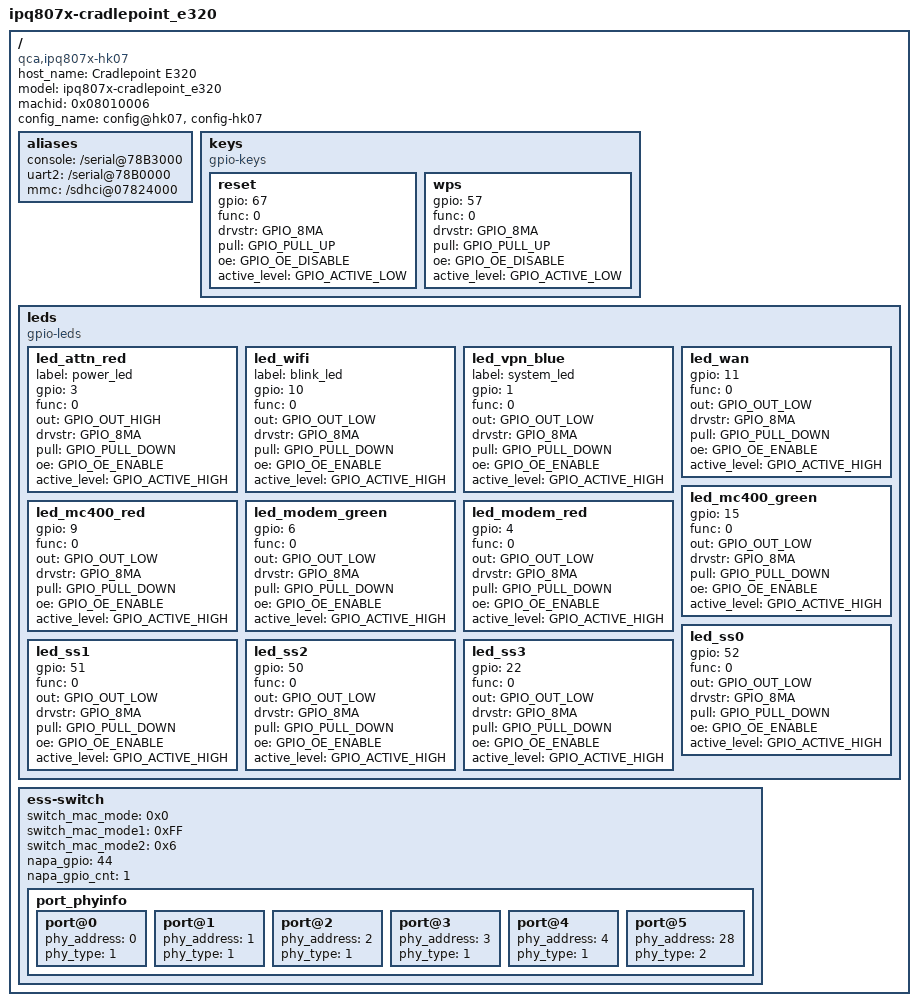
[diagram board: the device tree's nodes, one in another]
/*
 * Copyright (c) 2016 - 2018, The Linux Foundation. All rights reserved.
 *
 * This program is free software; you can redistribute it and/or modify
 * it under the terms of the GNU General Public License version 2 and
 * only version 2 as published by the Free Software Foundation.
 *
 * This program is distributed in the hope that it will be useful,
 * but WITHOUT ANY WARRANTY; without even the implied warranty of
 * MERCHANTABILITY or FITNESS FOR A PARTICULAR PURPOSE.  See the
 * GNU General Public License for more details.
 */

/dts-v1/;
#include "ipq807x-soc.dtsi"
#include <dt-bindings/qcom/gpio-ipq807x.h>
/ {
    host_name = "Cradlepoint E320";
	model = "ipq807x-cradlepoint_e320";
	compatible = "qca,ipq807x-hk07", "qca,ipq807x";
	machid = <0x08010006>;
	config_name = "config@hk07", "config-hk07";

	aliases {
		console = "/serial@78B3000";
		uart2 = "/serial@78B0000";
		mmc = "/sdhci@07824000";
	};

    keys {
		compatible = "gpio-keys";

        reset {
            gpio = <67>;
            func = <0>;
            drvstr = <GPIO_8MA>;
            pull = <GPIO_PULL_UP>;
            oe = <GPIO_OE_DISABLE>;
			active_level = <GPIO_ACTIVE_LOW>;
        };

        wps {
            gpio = <57>;
            func = <0>;
            drvstr = <GPIO_8MA>;
            pull = <GPIO_PULL_UP>;
            oe = <GPIO_OE_DISABLE>;
			active_level = <GPIO_ACTIVE_LOW>;
        };
    };

    leds {
		compatible = "gpio-leds";

        led_attn_red {
			label = "power_led";
            gpio = <3>;
            func = <0>;
            out = <GPIO_OUT_HIGH>;
            drvstr = <GPIO_8MA>;
            pull = <GPIO_PULL_DOWN>;
            oe = <GPIO_OE_ENABLE>;
            active_level = <GPIO_ACTIVE_HIGH>;
        };

        led_wifi {
			label = "blink_led";
            gpio = <10>;
            func = <0>;
            out = <GPIO_OUT_LOW>;
            drvstr = <GPIO_8MA>;
            pull = <GPIO_PULL_DOWN>;
            oe = <GPIO_OE_ENABLE>;
            active_level = <GPIO_ACTIVE_HIGH>;
        };

        led_vpn_blue {
			label = "system_led";
            gpio = <1>;
            func = <0>;
            out = <GPIO_OUT_LOW>;
            drvstr = <GPIO_8MA>;
            pull = <GPIO_PULL_DOWN>;
            oe = <GPIO_OE_ENABLE>;
            active_level = <GPIO_ACTIVE_HIGH>;
        };

        led_wan {
            gpio = <11>;
            func = <0>;
            out = <GPIO_OUT_LOW>;
            drvstr = <GPIO_8MA>;
            pull = <GPIO_PULL_DOWN>;
            oe = <GPIO_OE_ENABLE>;
            active_level = <GPIO_ACTIVE_HIGH>;
        };

        led_mc400_green {
            gpio = <15>;
            func = <0>;
            out = <GPIO_OUT_LOW>;
            drvstr = <GPIO_8MA>;
            pull = <GPIO_PULL_DOWN>;
            oe = <GPIO_OE_ENABLE>;
            active_level = <GPIO_ACTIVE_HIGH>;
        };

        led_mc400_red {
            gpio = <9>;
            func = <0>;
            out = <GPIO_OUT_LOW>;
            drvstr = <GPIO_8MA>;
            pull = <GPIO_PULL_DOWN>;
            oe = <GPIO_OE_ENABLE>;
            active_level = <GPIO_ACTIVE_HIGH>;
        };

        led_modem_green {
            gpio = <6>;
            func = <0>;
            out = <GPIO_OUT_LOW>;
            drvstr = <GPIO_8MA>;
            pull = <GPIO_PULL_DOWN>;
            oe = <GPIO_OE_ENABLE>;
            active_level = <GPIO_ACTIVE_HIGH>;
        };

        led_modem_red {
            gpio = <4>;
            func = <0>;
            out = <GPIO_OUT_LOW>;
            drvstr = <GPIO_8MA>;
            pull = <GPIO_PULL_DOWN>;
            oe = <GPIO_OE_ENABLE>;
            active_level = <GPIO_ACTIVE_HIGH>;
        };

        led_ss0 {
            gpio = <52>;
            func = <0>;
            out = <GPIO_OUT_LOW>;
            drvstr = <GPIO_8MA>;
            pull = <GPIO_PULL_DOWN>;
            oe = <GPIO_OE_ENABLE>;
            active_level = <GPIO_ACTIVE_HIGH>;
        };

        led_ss1 {
            gpio = <51>;
            func = <0>;
            out = <GPIO_OUT_LOW>;
            drvstr = <GPIO_8MA>;
            pull = <GPIO_PULL_DOWN>;
            oe = <GPIO_OE_ENABLE>;
            active_level = <GPIO_ACTIVE_HIGH>;
        };

        led_ss2 {
            gpio = <50>;
            func = <0>;
            out = <GPIO_OUT_LOW>;
            drvstr = <GPIO_8MA>;
            pull = <GPIO_PULL_DOWN>;
            oe = <GPIO_OE_ENABLE>;
            active_level = <GPIO_ACTIVE_HIGH>;
        };

        led_ss3 {
            gpio = <22>;
            func = <0>;
            out = <GPIO_OUT_LOW>;
            drvstr = <GPIO_8MA>;
            pull = <GPIO_PULL_DOWN>;
            oe = <GPIO_OE_ENABLE>;
            active_level = <GPIO_ACTIVE_HIGH>;
        };
    };

	ess-switch {
		switch_mac_mode = <0x0>;
		switch_mac_mode1 = <0xFF>;
		switch_mac_mode2 = <0x6>;
		napa_gpio = <44>;
		napa_gpio_cnt = <1>;
		port_phyinfo {
			port@0 {
				phy_address = <0>;
				phy_type = <1>;
			};
			port@1 {
				phy_address = <1>;
				phy_type = <1>;
			};
			port@2 {
				phy_address = <2>;
				phy_type = <1>;
			};
			port@3 {
				phy_address = <3>;
				phy_type = <1>;
			};
			port@4 {
				phy_address = <4>;
				phy_type = <1>;
			};
			port@5 {
				phy_address = <28>;
				phy_type = <2>;
			};
		};
	};
};
